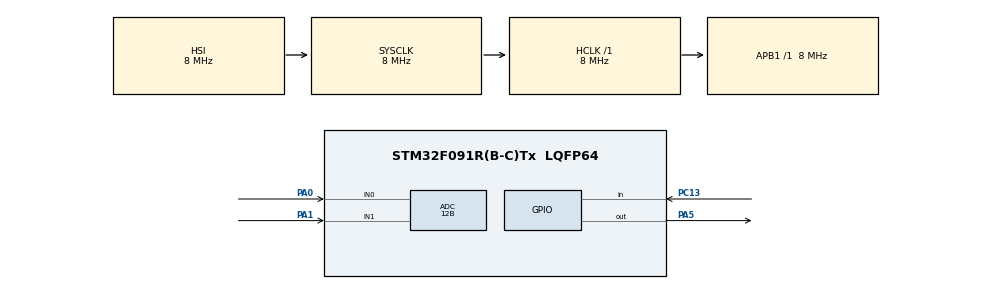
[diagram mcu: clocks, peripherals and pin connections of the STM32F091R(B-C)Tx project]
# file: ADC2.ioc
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ADC.ClockPrescaler=ADC_CLOCK_SYNC_PCLK_DIV4
ADC.ContinuousConvMode=ENABLE
ADC.EOCSelection=ADC_EOC_SEQ_CONV
ADC.Resolution=ADC_RESOLUTION_12B
ADC.SamplingTime=ADC_SAMPLETIME_239CYCLES_5
Mcu.Family=STM32F0
Mcu.Name=STM32F091R(B-C)Tx
Mcu.Package=LQFP64
PA0.Mode=IN0
PA0.Signal=ADC_IN0
PA1.Mode=IN1
PA1.Signal=ADC_IN1
PA5.Signal=GPIO_Output
PC13.Signal=GPIO_Input
ProjectManager.HeapSize=0x200
ProjectManager.StackSize=0x400
ProjectManager.TargetToolchain=SW4STM32
RCC.AHBFreq_Value=8000000
RCC.APB1Freq_Value=8000000
RCC.APB1TimFreq_Value=8000000
RCC.FLatency-AdvancedSettings=FLASH_LATENCY_0
RCC.HCLKFreq_Value=8000000
RCC.PLLDivider=RCC_PREDIV_DIV2
RCC.PLLMUL=RCC_PLL_MUL12
RCC.PREFETCH_ENABLE-AdvancedSettings=1
RCC.SYSCLKFreq_VALUE=8000000
board=NUCLEO-F091RC

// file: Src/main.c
/* USER CODE BEGIN Header */
/**
  ******************************************************************************
  * @file           : main.c
  * @brief          : Main program body
  ******************************************************************************
  * @attention
  *
  * <h2><center>&copy; Copyright (c) 2020 STMicroelectronics.
  * All rights reserved.</center></h2>
  *
  * This software component is licensed by ST under BSD 3-Clause license,
  * the "License"; You may not use this file except in compliance with the
  * License. You may obtain a copy of the License at:
  *                        opensource.org/licenses/BSD-3-Clause
  *
  ******************************************************************************
  */
/* USER CODE END Header */

#include "main.h"

ADC_HandleTypeDef hadc;

/* USER CODE BEGIN PV */
uint32_t adcValue[2]; //criar array com 2 entradas
/* USER CODE END PV */

void SystemClock_Config(void);
static void MX_GPIO_Init(void);
static void MX_ADC_Init(void);

int main(void)
{

  /* MCU Configuration--------------------------------------------------------*/

  /* Reset of all peripherals, Initializes the Flash interface and the Systick. */
  HAL_Init();

  /* Configure the system clock */
  SystemClock_Config();

  /* Initialize all configured peripherals */
  MX_GPIO_Init();
  MX_ADC_Init();
  /* USER CODE BEGIN 2 */
  HAL_ADC_Start(&hadc); //iniciar ADC
  /* USER CODE END 2 */

  /* Infinite loop */
  while (1)
  {

    /* USER CODE BEGIN 3 */

	  if(HAL_ADC_PollForConversion(&hadc,50) == HAL_OK) //primeira medição na primeira entrada do array
	  {
		adcValue[0] = HAL_ADC_GetValue(&hadc);
	  }
	  if(HAL_ADC_PollForConversion(&hadc,50) == HAL_OK) //segunda medição na segunda entrada do array
	  {
		adcValue[1] = HAL_ADC_GetValue(&hadc);
	  }
	  HAL_Delay(50);
  }
  /* USER CODE END 3 */
}

void SystemClock_Config(void)
{
  RCC_OscInitTypeDef RCC_OscInitStruct = {0};
  RCC_ClkInitTypeDef RCC_ClkInitStruct = {0};

  /** Initializes the CPU, AHB and APB busses clocks
  */
  RCC_OscInitStruct.OscillatorType = RCC_OSCILLATORTYPE_HSI;
  RCC_OscInitStruct.HSIState = RCC_HSI_ON;
  RCC_OscInitStruct.HSICalibrationValue = RCC_HSICALIBRATION_DEFAULT;
  RCC_OscInitStruct.PLL.PLLState = RCC_PLL_NONE;
  if (HAL_RCC_OscConfig(&RCC_OscInitStruct) != HAL_OK)
  {
    Error_Handler();
  }
  /** Initializes the CPU, AHB and APB busses clocks
  */
  RCC_ClkInitStruct.ClockType = RCC_CLOCKTYPE_HCLK|RCC_CLOCKTYPE_SYSCLK
                              |RCC_CLOCKTYPE_PCLK1;
  RCC_ClkInitStruct.SYSCLKSource = RCC_SYSCLKSOURCE_HSI;
  RCC_ClkInitStruct.AHBCLKDivider = RCC_SYSCLK_DIV1;
  RCC_ClkInitStruct.APB1CLKDivider = RCC_HCLK_DIV1;

  if (HAL_RCC_ClockConfig(&RCC_ClkInitStruct, FLASH_LATENCY_0) != HAL_OK)
  {
    Error_Handler();
  }
}

static void MX_ADC_Init(void)
{

  ADC_ChannelConfTypeDef sConfig = {0};

  /** Configure the global features of the ADC (Clock, Resolution, Data Alignment and number of conversion)
  */
  hadc.Instance = ADC1;
  hadc.Init.ClockPrescaler = ADC_CLOCK_SYNC_PCLK_DIV4;
  hadc.Init.Resolution = ADC_RESOLUTION_12B;
  hadc.Init.DataAlign = ADC_DATAALIGN_RIGHT;
  hadc.Init.ScanConvMode = ADC_SCAN_DIRECTION_FORWARD;
  hadc.Init.EOCSelection = ADC_EOC_SEQ_CONV;
  hadc.Init.LowPowerAutoWait = DISABLE;
  hadc.Init.LowPowerAutoPowerOff = DISABLE;
  hadc.Init.ContinuousConvMode = ENABLE;
  hadc.Init.DiscontinuousConvMode = DISABLE;
  hadc.Init.ExternalTrigConv = ADC_SOFTWARE_START;
  hadc.Init.ExternalTrigConvEdge = ADC_EXTERNALTRIGCONVEDGE_NONE;
  hadc.Init.DMAContinuousRequests = DISABLE;
  hadc.Init.Overrun = ADC_OVR_DATA_PRESERVED;
  if (HAL_ADC_Init(&hadc) != HAL_OK)
  {
    Error_Handler();
  }
  /** Configure for the selected ADC regular channel to be converted.
  */
  sConfig.Channel = ADC_CHANNEL_0;
  sConfig.Rank = ADC_RANK_CHANNEL_NUMBER;
  sConfig.SamplingTime = ADC_SAMPLETIME_239CYCLES_5;
  if (HAL_ADC_ConfigChannel(&hadc, &sConfig) != HAL_OK)
  {
    Error_Handler();
  }
  /** Configure for the selected ADC regular channel to be converted.
  */
  sConfig.Channel = ADC_CHANNEL_1;
  if (HAL_ADC_ConfigChannel(&hadc, &sConfig) != HAL_OK)
  {
    Error_Handler();
  }

}

static void MX_GPIO_Init(void)
{
  GPIO_InitTypeDef GPIO_InitStruct = {0};

  /* GPIO Ports Clock Enable */
  __HAL_RCC_GPIOC_CLK_ENABLE();
  __HAL_RCC_GPIOA_CLK_ENABLE();

  /*Configure GPIO pin Output Level */
  HAL_GPIO_WritePin(GPIOA, GPIO_PIN_5, GPIO_PIN_RESET);

  /*Configure GPIO pin : PC13 */
  GPIO_InitStruct.Pin = GPIO_PIN_13;
  GPIO_InitStruct.Mode = GPIO_MODE_INPUT;
  GPIO_InitStruct.Pull = GPIO_NOPULL;
  HAL_GPIO_Init(GPIOC, &GPIO_InitStruct);

  /*Configure GPIO pin : PA5 */
  GPIO_InitStruct.Pin = GPIO_PIN_5;
  GPIO_InitStruct.Mode = GPIO_MODE_OUTPUT_PP;
  GPIO_InitStruct.Pull = GPIO_NOPULL;
  GPIO_InitStruct.Speed = GPIO_SPEED_FREQ_LOW;
  HAL_GPIO_Init(GPIOA, &GPIO_InitStruct);

}

void Error_Handler(void)
{
}

/************************ (C) COPYRIGHT STMicroelectronics *****END OF FILE****/
